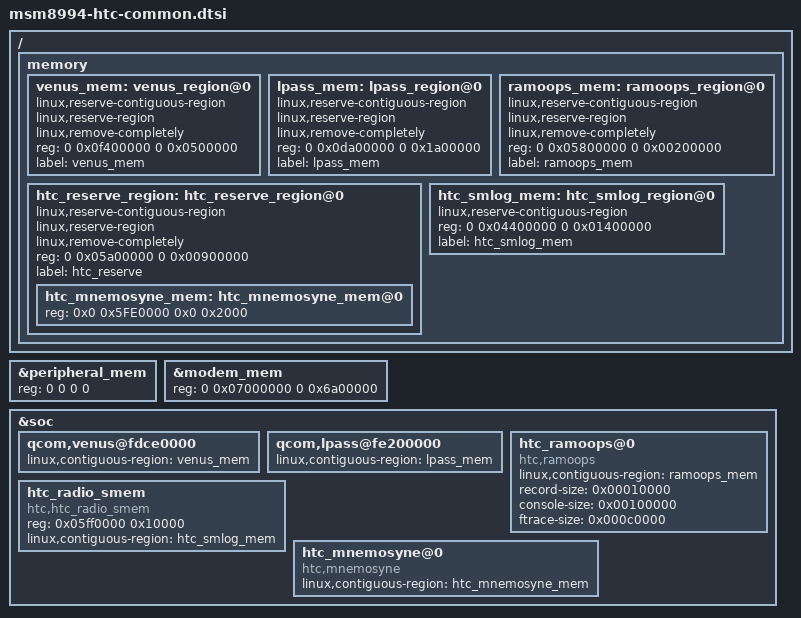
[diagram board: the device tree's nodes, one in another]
/*
 * msm8994-htc-common: common configs of HTC msm8994 projects
 */

&peripheral_mem {
	/* Original: reg = <0 0x0c800000 0 0x1b00000>; */
	reg = <0 0 0 0>;
};

&modem_mem {
	reg = <0 0x07000000 0 0x6a00000>;
};

/ {
	memory {
		venus_mem: venus_region@0 {
			linux,reserve-contiguous-region;
			linux,reserve-region;
			linux,remove-completely;
			reg = <0 0x0f400000 0 0x0500000>;
			label = "venus_mem";
		};

		lpass_mem: lpass_region@0 {
			linux,reserve-contiguous-region;
			linux,reserve-region;
			linux,remove-completely;
			reg = <0 0x0da00000 0 0x1a00000>;
			label = "lpass_mem";
		};

		ramoops_mem: ramoops_region@0 {
			linux,reserve-contiguous-region;
			linux,reserve-region;
			linux,remove-completely;
			reg = <0 0x05800000 0 0x00200000>; /* 2 MB */
			label = "ramoops_mem";
		};

		htc_reserve_region: htc_reserve_region@0 {
			linux,reserve-contiguous-region;
			linux,reserve-region;
			linux,remove-completely;
			reg = <0 0x05a00000 0 0x00900000>; /* 9 MB */
			label = "htc_reserve";

			#address-cells = <2>;
			#size-cells = <2>;
			htc_mnemosyne_mem: htc_mnemosyne_mem@0 {
				reg = <0x0 0x5FE0000 0x0 0x2000>;
			};
		};

                htc_smlog_mem: htc_smlog_region@0 {
                        linux,reserve-contiguous-region;
                        reg = <0 0x04400000 0 0x01400000>; /* 20 MB */
                        label = "htc_smlog_mem";
                };
	};
};

&soc {
	qcom,venus@fdce0000 {
		/* Original: linux,contiguous-region = <&peripheral_mem>; */
		linux,contiguous-region = <&venus_mem>;
	};

	qcom,lpass@fe200000 {
		/* Original: linux,contiguous-region = <&peripheral_mem>; */
		linux,contiguous-region = <&lpass_mem>;
	};

	htc_ramoops@0 {
		compatible = "htc,ramoops";
		linux,contiguous-region = <&ramoops_mem>;
		record-size  = <0x00010000>;  /*   64 KB */
		console-size = <0x00100000>;  /* 1024 KB */
		ftrace-size  = <0x000c0000>;  /*  768 KB */
	};

        htc_radio_smem {
                compatible = "htc,htc_radio_smem";
                reg = <0x05ff0000 0x10000>;
                linux,contiguous-region = <&htc_smlog_mem>;
                reg-names = "smem-start-addr";
        };

	htc_mnemosyne@0 {
		compatible = "htc,mnemosyne";
		linux,contiguous-region = <&htc_mnemosyne_mem>;
	};
};
